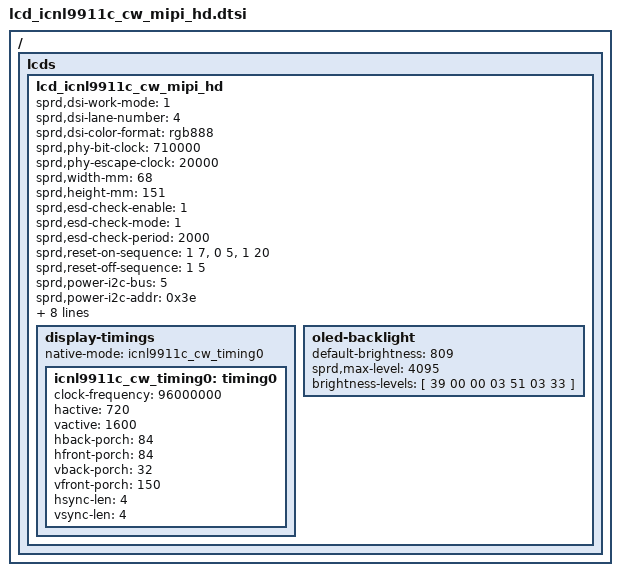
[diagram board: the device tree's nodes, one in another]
/ {
	fragment {
		target-path = "/";
		__overlay__ {
			lcds {
				lcd_icnl9911c_cw_mipi_hd: lcd_icnl9911c_cw_mipi_hd {
					sprd,dsi-work-mode = <1>; /* video burst mode*/
					sprd,dsi-lane-number = <4>;
					sprd,dsi-color-format = "rgb888";

					sprd,phy-bit-clock = <710000>;	/* kbps */
					sprd,phy-escape-clock = <20000>;/* kHz */

					sprd,width-mm = <68>;
					sprd,height-mm = <151>;

					sprd,esd-check-enable = <1>;
					sprd,esd-check-mode = <1>; /*1TE 0reg */
					sprd,esd-check-period = <2000>;
					/* sprd,esd-check-register = <0x0A>; */
					/* sprd,esd-check-value = <0x9C>; */

					sprd,reset-on-sequence = <1 7>, <0 5>, <1 20>;
					sprd,reset-off-sequence = <1 5>;

					sprd,power-i2c-bus = <5>;
					sprd,power-i2c-addr = <0x3e>;
					sprd,power-i2c-reg = [00 01 03];
					sprd,power-i2c-val = [14 14 83];

					/*sprd,use-dcs-write;*/
					sprd,initial-command = [
						39 00 00 03 F0 5A 59
						39 00 00 03 F1 A5 A6
						39 00 00 1F B0 89 88 87 86 89 00 00 00 55 55 33 33 05 00 00 93 00 00 0F 05 04 03 02 01 02 03 04 04 00 00
						39 00 00 21 B1 53 54 85 85 75 00 00 75 00 00 04 08 54 00 00 00 44 40 02 01 40 02 01 40 02 01 40 02 01 00 00 00
						39 00 00 12 B2 54 C4 82 05 40 02 01 40 02 01 05 05 54 0C 0C 0D 0B
						39 00 00 1C B3 00 11 07 11 07 26 26 91 A2 33 44 00 26 00 18 01 02 08 20 30 61 07 41 20 40 00 40
						39 00 00 1D B4 00 02 02 02 00 02 22 23 23 02 0D 0F 11 13 02 05 07 02 00 00 00 02 FF FF FC 83 80 00
						39 00 00 1D B5 00 02 02 02 00 02 22 23 23 02 0C 0E 10 12 02 04 06 02 00 00 00 02 FF FF FC 83 80 00
						39 00 00 19 B8 00 00 00 00 00 00 00 00 00 00 00 00 AA AA AA AA AA A0 AA AA AA AA AA A0
						39 00 00 0E BB 01 02 03 05 04 07 08 46 0A 4B 00 09 0A
						39 00 00 0F BC 00 00 00 00 02 20 FF 00 03 13 01 73 33 02
						39 00 00 0B BD E9 02 4F CF 72 A4 08 44 AE 15
						39 00 00 0B BE 6E 6E 5A 3C 0C 77 43 07 0E 0E
						39 00 00 09 BF 07 25 07 25 7F 00 11 04
						39 00 00 0A C0 10 00 1F FF FF FF 00 FF 00
						39 00 00 14 C1 C0 20 20 96 04 54 54 04 2A 40 36 00 07 C0 10 FF C0 00 C0
						39 00 00 07 C2 CC 01 10 00 01 30
						39 00 00 0C C3 06 00 FF 00 FF 00 00 81 01 00 00
						39 00 00 0B C4 84 01 2B 41 00 3C 00 03 03 2E
						39 00 00 0C C5 03 1C B8 B8 30 10 42 66 08 0E 14
						39 00 00 0B C6 87 9B 2A 29 29 31 7F 34 08 04
						39 00 00 06 D0 80 0D FF 0F 63
						39 00 00 02 D2 42
						39 00 00 17 C7 FB CE AE 96 68 48 16 68 2F 03 D6 A4 FA CD B0 86 6E 4B 1E 7F E0 00
						39 00 00 17 C8 FB CE AE 96 68 48 16 68 2F 03 D6 A4 FA CD B0 86 6E 4B 1E 7F E0 00
						39 00 00 02 CB 00
						39 00 00 1B E0 30 00 80 88 11 3F 22 62 DF A0 04 CC 01 FF F6 FF F0 FD FF FD F8 F5 FC FC FD FF
						39 00 00 18 E1 EF FE FE FE FE EE F0 20 33 FF 00 00 6A 90 C0 0D 6A F0 3E FF 00 06 40 //20KHZ
						39 00 00 05 FE FF FF FF 40
						39 00 00 03 F1 5A 59
						39 00 00 03 F0 A5 A6
						39 00 00 02 35 00
						39 00 00 02 53 2C
						05 5A 00 01 11
						05 0A 00 01 29
						39 00 00 02 26 01
					];

					sprd,sleep-in-command = [
						23 01 00 02 26 08
						13 14 00 01 28
						13 78 00 01 10
						];

					sprd,sleep-out-command = [
						05 78 00 01 11
						05 14 00 01 29
						15 00 00 02 26 01
						];


					display-timings {
						native-mode = <&icnl9911c_cw_timing0>;
						icnl9911c_cw_timing0: timing0 {
							clock-frequency = <96000000>;
							hactive = <720>;
							vactive = <1600>;
							hback-porch = <84>;
							hfront-porch = <84>;
							vback-porch = <32>;
							vfront-porch = <150>;
							hsync-len = <4>;
							vsync-len = <4>;
						};
					};

					oled-backlight {
						default-brightness = <809>;
						sprd,max-level = <4095>;
						brightness-levels = [
            		    				39 00 00 03 51 03 33
						];
					};
				};
			};
		};
	};
};
